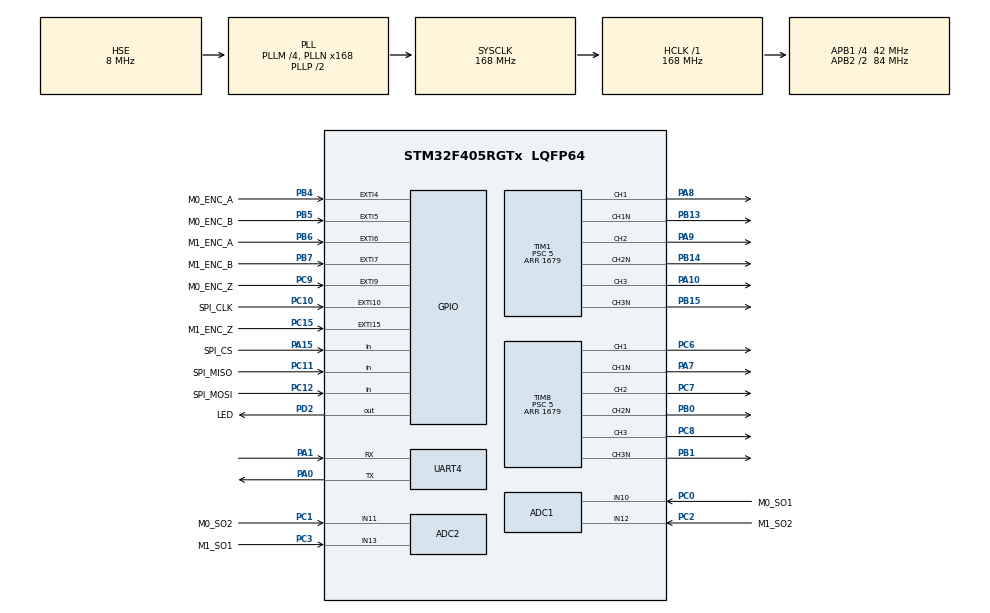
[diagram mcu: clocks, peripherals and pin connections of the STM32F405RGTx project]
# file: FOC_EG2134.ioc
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ADC1.Channel-0\#ChannelRegularConversion=ADC_CHANNEL_10
ADC1.Channel-2\#ChannelRegularConversion=ADC_CHANNEL_12
ADC1.ClockPrescaler=ADC_CLOCK_SYNC_PCLK_DIV4
ADC1.ContinuousConvMode=DISABLE
ADC1.DMAContinuousRequests=ENABLE
ADC1.EOCSelection=ADC_EOC_SEQ_CONV
ADC1.ExternalTrigConv=ADC_SOFTWARE_START
ADC1.ExternalTrigConvEdge=ADC_EXTERNALTRIGCONVEDGE_NONE
ADC1.Mode=ADC_DUALMODE_REGSIMULT
ADC1.NbrOfConversion=2
ADC1.NbrOfConversionFlag=1
ADC1.Rank-0\#ChannelRegularConversion=1
ADC1.Rank-2\#ChannelRegularConversion=2
ADC1.SamplingTime-0\#ChannelRegularConversion=ADC_SAMPLETIME_56CYCLES
ADC1.SamplingTime-2\#ChannelRegularConversion=ADC_SAMPLETIME_56CYCLES
ADC1.ScanConvMode=ENABLE
ADC1.master=1
ADC2.Channel-0\#ChannelRegularConversion=ADC_CHANNEL_11
ADC2.Channel-1\#ChannelRegularConversion=ADC_CHANNEL_13
ADC2.DMAAccessMode=ADC_DMAACCESSMODE_2
ADC2.DMAContinuousRequests=DISABLE
ADC2.DiscontinuousConvMode=DISABLE
ADC2.EOCSelection=ADC_EOC_SEQ_CONV
ADC2.Mode=ADC_DUALMODE_REGSIMULT
ADC2.NbrOfConversion=2
ADC2.NbrOfConversionFlag=1
ADC2.Rank-0\#ChannelRegularConversion=1
ADC2.Rank-1\#ChannelRegularConversion=2
ADC2.SamplingTime-0\#ChannelRegularConversion=ADC_SAMPLETIME_56CYCLES
ADC2.SamplingTime-1\#ChannelRegularConversion=ADC_SAMPLETIME_56CYCLES
Dma.ADC1.0.Direction=DMA_PERIPH_TO_MEMORY
Dma.ADC1.0.FIFOMode=DMA_FIFOMODE_DISABLE
Dma.ADC1.0.Instance=DMA2_Stream0
Dma.ADC1.0.MemDataAlignment=DMA_MDATAALIGN_WORD
Dma.ADC1.0.MemInc=DMA_MINC_ENABLE
Dma.ADC1.0.Mode=DMA_CIRCULAR
Dma.ADC1.0.PeriphDataAlignment=DMA_PDATAALIGN_WORD
Dma.ADC1.0.PeriphInc=DMA_PINC_DISABLE
Dma.ADC1.0.Priority=DMA_PRIORITY_LOW
Dma.Request0=ADC1
Mcu.Family=STM32F4
Mcu.Name=STM32F405RGTx
Mcu.Package=LQFP64
NVIC.ADC_IRQn=true\:0\:0\:false\:false\:true\:true\:true\:true
NVIC.DMA2_Stream0_IRQn=true\:0\:0\:false\:false\:true\:false\:true\:true
NVIC.EXTI15_10_IRQn=true\:2\:0\:true\:false\:true\:true\:true\:true
NVIC.EXTI4_IRQn=true\:2\:0\:true\:false\:true\:true\:true\:true
NVIC.EXTI9_5_IRQn=true\:2\:0\:true\:false\:true\:true\:true\:true
NVIC.PriorityGroup=NVIC_PRIORITYGROUP_4
NVIC.TIM1_UP_TIM10_IRQn=true\:0\:0\:false\:false\:true\:true\:true\:true
NVIC.TIM6_DAC_IRQn=true\:3\:0\:true\:false\:true\:true\:true\:true
NVIC.TIM7_IRQn=true\:0\:0\:true\:false\:true\:true\:true\:true
NVIC.UART4_IRQn=true\:0\:0\:false\:false\:true\:true\:true\:true
PA0-WKUP.Mode=Asynchronous
PA0-WKUP.Signal=UART4_TX
PA1.Mode=Asynchronous
PA1.Signal=UART4_RX
PA10.Signal=S_TIM1_CH3
PA13.Mode=Serial_Wire
PA13.Signal=SYS_JTMS-SWDIO
PA14.Mode=Serial_Wire
PA14.Signal=SYS_JTCK-SWCLK
PA15.GPIO_Label=SPI_CS
PA15.Signal=GPIO_Input
PA7.Mode=PWM Generation1 CH1 CH1N
PA7.Signal=TIM8_CH1N
PA8.Signal=S_TIM1_CH1
PA9.Signal=S_TIM1_CH2
PB0.Mode=PWM Generation2 CH2 CH2N
PB0.Signal=TIM8_CH2N
PB1.Mode=PWM Generation3 CH3 CH3N
PB1.Signal=TIM8_CH3N
PB13.Mode=PWM Generation1 CH1 CH1N
PB13.Signal=TIM1_CH1N
PB14.Mode=PWM Generation2 CH2 CH2N
PB14.Signal=TIM1_CH2N
PB15.Mode=PWM Generation3 CH3 CH3N
PB15.Signal=TIM1_CH3N
PB4.GPIO_Label=M0_ENC_A
PB4.GPIO_ModeDefaultEXTI=GPIO_MODE_IT_RISING_FALLING
PB4.GPIO_PuPd=GPIO_PULLUP
PB4.Signal=GPXTI4
PB5.GPIO_Label=M0_ENC_B
PB5.GPIO_ModeDefaultEXTI=GPIO_MODE_IT_RISING_FALLING
PB5.GPIO_PuPd=GPIO_PULLUP
PB5.Signal=GPXTI5
PB6.GPIO_Label=M1_ENC_A
PB6.GPIO_ModeDefaultEXTI=GPIO_MODE_IT_RISING_FALLING
PB6.GPIO_PuPd=GPIO_PULLUP
PB6.Signal=GPXTI6
PB7.GPIO_Label=M1_ENC_B
PB7.GPIO_ModeDefaultEXTI=GPIO_MODE_IT_RISING_FALLING
PB7.GPIO_PuPd=GPIO_PULLUP
PB7.Signal=GPXTI7
PC0.GPIO_Label=M0_SO1
PC0.Signal=ADCx_IN10
PC1.GPIO_Label=M0_SO2
PC1.Signal=ADCx_IN11
PC10.GPIO_Label=SPI_CLK
PC10.GPIO_ModeDefaultEXTI=GPIO_MODE_IT_RISING
PC10.GPIO_PuPd=GPIO_PULLDOWN
PC10.Signal=GPXTI10
PC11.GPIO_Label=SPI_MISO
PC11.Signal=GPIO_Input
PC12.GPIO_Label=SPI_MOSI
PC12.Signal=GPIO_Input
PC15-OSC32_OUT.GPIO_Label=M1_ENC_Z
PC15-OSC32_OUT.GPIO_ModeDefaultEXTI=GPIO_MODE_IT_RISING_FALLING
PC15-OSC32_OUT.GPIO_PuPd=GPIO_PULLUP
PC15-OSC32_OUT.Signal=GPXTI15
PC2.GPIO_Label=M1_SO2
PC2.Signal=ADCx_IN12
PC3.GPIO_Label=M1_SO1
PC3.Signal=ADCx_IN13
PC6.Signal=S_TIM8_CH1
PC7.Signal=S_TIM8_CH2
PC8.Signal=S_TIM8_CH3
PC9.GPIO_Label=M0_ENC_Z
PC9.GPIO_ModeDefaultEXTI=GPIO_MODE_IT_RISING_FALLING
PC9.GPIO_PuPd=GPIO_PULLUP
PC9.Signal=GPXTI9
PD2.GPIO_Label=LED
PD2.GPIO_PuPd=GPIO_PULLUP
PD2.PinState=GPIO_PIN_RESET
PD2.Signal=GPIO_Output
PH0-OSC_IN.Mode=HSE-External-Oscillator
PH0-OSC_IN.Signal=RCC_OSC_IN
PH1-OSC_OUT.Mode=HSE-External-Oscillator
PH1-OSC_OUT.Signal=RCC_OSC_OUT
ProjectManager.HeapSize=0x200
ProjectManager.StackSize=0x400
ProjectManager.TargetToolchain=STM32CubeIDE
RCC.48MHZClocksFreq_Value=84000000
RCC.AHBFreq_Value=168000000
RCC.APB1CLKDivider=RCC_HCLK_DIV4
RCC.APB1Freq_Value=42000000
RCC.APB1TimFreq_Value=84000000
RCC.APB2CLKDivider=RCC_HCLK_DIV2
RCC.APB2Freq_Value=84000000
RCC.APB2TimFreq_Value=168000000
RCC.CortexFreq_Value=168000000
RCC.HCLKFreq_Value=168000000
RCC.HSE_VALUE=8000000
RCC.HSI_VALUE=16000000
RCC.LSE_VALUE=32768
RCC.PLLM=4
RCC.PLLN=168
RCC.PLLSourceVirtual=RCC_PLLSOURCE_HSE
RCC.SYSCLKFreq_VALUE=168000000
RCC.SYSCLKSource=RCC_SYSCLKSOURCE_PLLCLK
RCC.VCOOutputFreq_Value=336000000
SH.ADCx_IN10.0=ADC1_IN10,IN10
SH.ADCx_IN11.0=ADC2_IN11,IN11
SH.ADCx_IN12.0=ADC1_IN12,IN12
SH.ADCx_IN13.0=ADC2_IN13,IN13
SH.S_TIM1_CH1.0=TIM1_CH1,PWM Generation1 CH1 CH1N
SH.S_TIM1_CH2.0=TIM1_CH2,PWM Generation2 CH2 CH2N
SH.S_TIM1_CH3.0=TIM1_CH3,PWM Generation3 CH3 CH3N
SH.S_TIM8_CH1.0=TIM8_CH1,PWM Generation1 CH1 CH1N
SH.S_TIM8_CH2.0=TIM8_CH2,PWM Generation2 CH2 CH2N
SH.S_TIM8_CH3.0=TIM8_CH3,PWM Generation3 CH3 CH3N
TIM1.Channel-PWM\ Generation1\ CH1\ CH1N=TIM_CHANNEL_1
TIM1.Channel-PWM\ Generation2\ CH2\ CH2N=TIM_CHANNEL_2
TIM1.Channel-PWM\ Generation3\ CH3\ CH3N=TIM_CHANNEL_3
TIM1.ClockDivision=TIM_CLOCKDIVISION_DIV1
TIM1.CounterMode=TIM_COUNTERMODE_CENTERALIGNED2
TIM1.DeadTime=30
TIM1.OCNPolarity_1=TIM_OCNPOLARITY_HIGH
TIM1.Period=1679
TIM1.Prescaler=5
TIM1.TIM_MasterOutputTrigger=TIM_TRGO_ENABLE
TIM1.TIM_MasterSlaveMode=TIM_MASTERSLAVEMODE_ENABLE
TIM10.Period=2499
TIM10.Prescaler=83
TIM6.Period=999
TIM6.Prescaler=83
TIM7.Period=99
TIM7.Prescaler=41
TIM8.Channel-PWM\ Generation1\ CH1\ CH1N=TIM_CHANNEL_1
TIM8.Channel-PWM\ Generation2\ CH2\ CH2N=TIM_CHANNEL_2
TIM8.Channel-PWM\ Generation3\ CH3\ CH3N=TIM_CHANNEL_3
TIM8.ClockDivision=TIM_CLOCKDIVISION_DIV1
TIM8.CounterMode=TIM_COUNTERMODE_CENTERALIGNED2
TIM8.DeadTime=30
TIM8.Period=1679
TIM8.Prescaler=5
TIM8.TIM_MasterOutputTrigger=TIM_TRGO_UPDATE
TIM8.TIM_MasterSlaveMode=TIM_MASTERSLAVEMODE_DISABLE
UART4.VirtualMode=Asynchronous
VP_TIM10_VS_ClockSourceINT.Mode=Enable_Timer
VP_TIM1_VS_ClockSourceINT.Mode=Internal
VP_TIM6_VS_ClockSourceINT.Mode=Enable_Timer
VP_TIM7_VS_ClockSourceINT.Mode=Enable_Timer
VP_TIM8_VS_ClockSourceINT.Mode=Internal
VP_TIM8_VS_ClockSourceITR.Mode=TriggerSource_ITR0
VP_TIM8_VS_ControllerModeTrigger.Mode=Trigger Mode
board=custom

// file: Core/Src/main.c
/* USER CODE BEGIN Header */
/**
  ******************************************************************************
  * @file           : main.c
  * @brief          : Main program body
  ******************************************************************************
  * @attention
  *
  * Copyright (c) 2026 STMicroelectronics.
  * All rights reserved.
  *
  * This software is licensed under terms that can be found in the LICENSE file
  * in the root directory of this software component.
  * If no LICENSE file comes with this software, it is provided AS-IS.
  *
  ******************************************************************************
  */
/* USER CODE END Header */
#include "main.h"
#include "adc.h"
#include "dma.h"
#include "tim.h"
#include "usart.h"
#include "gpio.h"

/* USER CODE BEGIN Includes */
#include "../../DriveLayer/Inc/PWM_EG2134.h"
#include "../../DriveLayer/Inc/UART2.h"
#include "../../MiddleLayer/Inc/svpwm.h"
#include "../../DriveLayer/Inc/Motor.h"
#include "../../MiddleLayer/Inc/park_transformation.h"
/* USER CODE END Includes */

void SystemClock_Config(void);

int main(void)
{

  /* MCU Configuration--------------------------------------------------------*/

  /* Reset of all peripherals, Initializes the Flash interface and the Systick. */
  HAL_Init();

  /* Configure the system clock */
  SystemClock_Config();

  /* Initialize all configured peripherals */
  MX_GPIO_Init();
  MX_DMA_Init();
  MX_ADC1_Init();
  MX_ADC2_Init();
  MX_TIM1_Init();
  MX_TIM8_Init();
  MX_TIM6_Init();
  MX_TIM7_Init();
  MX_UART4_Init();
  MX_TIM10_Init();
  /* USER CODE BEGIN 2 */
  //HAL_Delay(2000);
  uart2_Init();
  Motor_Init();
	//motor_M0.Id_LOOP->Expactation_value = 0.0f;
	//motor_M0.Iq_LOOP->Expactation_value = -200.0f;

  /* USER CODE END 2 */

  /* Infinite loop */
  /* USER CODE BEGIN WHILE */
  while (1)
  {
		  //HAL_Delay(10);
		  //HAL_GPIO_WritePin(LED_GPIO_Port, LED_Pin, GPIO_PIN_SET);
		 //HAL_Delay(500);
		  //HAL_GPIO_WritePin(LED_GPIO_Port, LED_Pin, GPIO_PIN_RESET);

		  uasrt2_printf("%d,%d,%d,%d\n",
				  	  motor_M0.Current_PhaseB,
					  motor_M0.Current_PhaseC,
					  motor_M1.Current_PhaseB,
					  motor_M1.Current_PhaseC
					  );
		  //EG2134_Test(motor_M0.motorDrive, 150, 1);
		  usart2_send_loop();
    /* USER CODE END WHILE */

  }
}

void SystemClock_Config(void)
{
  RCC_OscInitTypeDef RCC_OscInitStruct = {0};
  RCC_ClkInitTypeDef RCC_ClkInitStruct = {0};

  /** Configure the main internal regulator output voltage
  */
  __HAL_RCC_PWR_CLK_ENABLE();
  __HAL_PWR_VOLTAGESCALING_CONFIG(PWR_REGULATOR_VOLTAGE_SCALE1);

  /** Initializes the RCC Oscillators according to the specified parameters
  * in the RCC_OscInitTypeDef structure.
  */
  RCC_OscInitStruct.OscillatorType = RCC_OSCILLATORTYPE_HSE;
  RCC_OscInitStruct.HSEState = RCC_HSE_ON;
  RCC_OscInitStruct.PLL.PLLState = RCC_PLL_ON;
  RCC_OscInitStruct.PLL.PLLSource = RCC_PLLSOURCE_HSE;
  RCC_OscInitStruct.PLL.PLLM = 4;
  RCC_OscInitStruct.PLL.PLLN = 168;
  RCC_OscInitStruct.PLL.PLLP = RCC_PLLP_DIV2;
  RCC_OscInitStruct.PLL.PLLQ = 4;
  if (HAL_RCC_OscConfig(&RCC_OscInitStruct) != HAL_OK)
  {
    Error_Handler();
  }

  /** Initializes the CPU, AHB and APB buses clocks
  */
  RCC_ClkInitStruct.ClockType = RCC_CLOCKTYPE_HCLK|RCC_CLOCKTYPE_SYSCLK
                              |RCC_CLOCKTYPE_PCLK1|RCC_CLOCKTYPE_PCLK2;
  RCC_ClkInitStruct.SYSCLKSource = RCC_SYSCLKSOURCE_PLLCLK;
  RCC_ClkInitStruct.AHBCLKDivider = RCC_SYSCLK_DIV1;
  RCC_ClkInitStruct.APB1CLKDivider = RCC_HCLK_DIV4;
  RCC_ClkInitStruct.APB2CLKDivider = RCC_HCLK_DIV2;

  if (HAL_RCC_ClockConfig(&RCC_ClkInitStruct, FLASH_LATENCY_5) != HAL_OK)
  {
    Error_Handler();
  }
}

void Error_Handler(void)
{
  __disable_irq();
  while (1)
  {
  }
}
